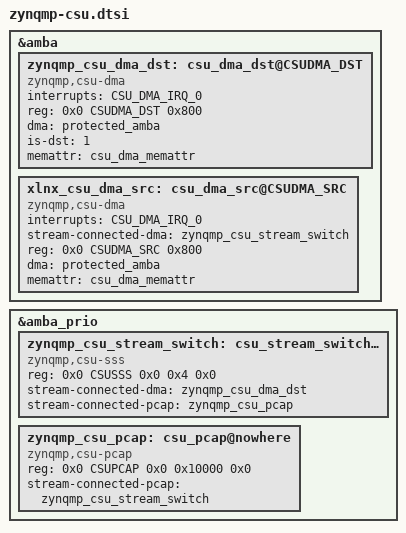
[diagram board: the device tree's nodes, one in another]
/*
 * ZynqMP IO include file
 *
 * Copyright (c) 2018, Xilinx Inc
 * All rights reserved.
 *
 * Redistribution and use in source and binary forms, with or without
 * modification, are permitted provided that the following conditions are met:
 *     * Redistributions of source code must retain the above copyright
 *       notice, this list of conditions and the following disclaimer.
 *     * Redistributions in binary form must reproduce the above copyright
 *       notice, this list of conditions and the following disclaimer in the
 *       documentation and/or other materials provided with the distribution.
 *     * Neither the name of the <organization> nor the
 *       names of its contributors may be used to endorse or promote products
 *       derived from this software without specific prior written permission.
 *
 * THIS SOFTWARE IS PROVIDED BY THE COPYRIGHT HOLDERS AND CONTRIBUTORS "AS IS" AND
 * ANY EXPRESS OR IMPLIED WARRANTIES, INCLUDING, BUT NOT LIMITED TO, THE IMPLIED
 * WARRANTIES OF MERCHANTABILITY AND FITNESS FOR A PARTICULAR PURPOSE ARE
 * DISCLAIMED. IN NO EVENT SHALL <COPYRIGHT HOLDER> BE LIABLE FOR ANY
 * DIRECT, INDIRECT, INCIDENTAL, SPECIAL, EXEMPLARY, OR CONSEQUENTIAL DAMAGES
 * (INCLUDING, BUT NOT LIMITED TO, PROCUREMENT OF SUBSTITUTE GOODS OR SERVICES;
 * LOSS OF USE, DATA, OR PROFITS; OR BUSINESS INTERRUPTION) HOWEVER CAUSED AND
 * ON ANY THEORY OF LIABILITY, WHETHER IN CONTRACT, STRICT LIABILITY, OR TORT
 * (INCLUDING NEGLIGENCE OR OTHERWISE) ARISING IN ANY WAY OUT OF THE USE OF THIS
 * SOFTWARE, EVEN IF ADVISED OF THE POSSIBILITY OF SUCH DAMAGE.
 */

#define CSUSSS			0xffca0008
#define CSUDMA_SRC		0xFFC80000
#define CSUDMA_DST		0xFFC80800
#define CSUDMA			0xFFC80000
#define CSUPCAP			0xFFCA3000

&amba {
	zynqmp_csu_dma_dst: csu_dma_dst@CSUDMA_DST {
		compatible = "zynqmp,csu-dma";
		interrupts = <CSU_DMA_IRQ_0>;
		reg = <0x0 CSUDMA_DST 0x800>;
		dma = <&protected_amba>;
		is-dst = <1>;
		memattr = <&csu_dma_memattr>;
	};
	xlnx_csu_dma_src: csu_dma_src@CSUDMA_SRC {
		compatible = "zynqmp,csu-dma";
		interrupts = <CSU_DMA_IRQ_0>;
		stream-connected-dma = <&zynqmp_csu_stream_switch> ;
		reg = <0x0 CSUDMA_SRC 0x800>;
		dma = <&protected_amba>;
		memattr = <&csu_dma_memattr>;
	};
};

&amba_prio {
	zynqmp_csu_stream_switch: csu_stream_switch@ffcc0200 {
		compatible = "zynqmp,csu-sss";
		reg = <0x0 CSUSSS 0x0 0x4 0x0>;
		stream-connected-dma = <&zynqmp_csu_dma_dst> ;
		stream-connected-pcap = <&zynqmp_csu_pcap> ;
	};
	zynqmp_csu_pcap: csu_pcap@nowhere {
		compatible = "zynqmp,csu-pcap";
		reg = <0x0 CSUPCAP 0x0 0x10000 0x0>;
		stream-connected-pcap = <&zynqmp_csu_stream_switch> ;
	};
};
